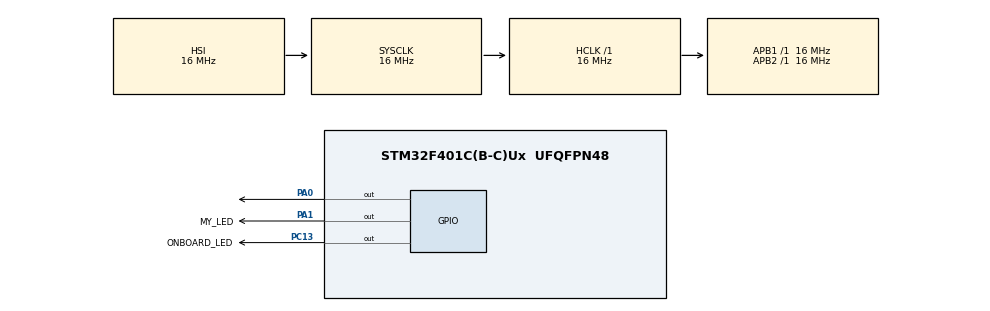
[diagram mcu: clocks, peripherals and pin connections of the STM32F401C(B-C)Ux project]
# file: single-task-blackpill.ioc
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FREERTOS.INCLUDE_vTaskDelayUntil=1
FREERTOS.Tasks01=defaultTask,0,128,StartDefaultTask,Default,NULL,Dynamic,NULL,NULL
Mcu.Family=STM32F4
Mcu.Name=STM32F401C(B-C)Ux
Mcu.Package=UFQFPN48
NVIC.PriorityGroup=NVIC_PRIORITYGROUP_4
NVIC.TIM1_UP_TIM10_IRQn=true\:15\:0\:false\:false\:true\:false\:false\:true\:true
NVIC.TimeBase=TIM1_UP_TIM10_IRQn
NVIC.TimeBaseIP=TIM1
PA0-WKUP.Signal=GPIO_Output
PA1.GPIO_Label=MY_LED
PA1.Signal=GPIO_Output
PC13-ANTI_TAMP.GPIO_Label=ONBOARD_LED
PC13-ANTI_TAMP.Signal=GPIO_Output
ProjectManager.HeapSize=0x200
ProjectManager.StackSize=0x400
ProjectManager.TargetToolchain=STM32CubeIDE
RCC.AHBFreq_Value=16000000
RCC.APB1Freq_Value=16000000
RCC.APB2Freq_Value=16000000
RCC.CortexFreq_Value=16000000
RCC.HSE_VALUE=25000000
RCC.HSI_VALUE=16000000
RCC.LSE_VALUE=32768
RCC.SYSCLKFreq_VALUE=16000000
RCC.VCOOutputFreq_Value=192000000
VP_FREERTOS_VS_CMSIS_V1.Mode=CMSIS_V1
VP_SYS_VS_tim1.Mode=TIM1
board=custom

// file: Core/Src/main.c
/* USER CODE BEGIN Header */
/**
  ******************************************************************************
  * @file           : main.c
  * @brief          : Main program body
  ******************************************************************************
  * @attention
  *
  * Copyright (c) 2025 STMicroelectronics.
  * All rights reserved.
  *
  * This software is licensed under terms that can be found in the LICENSE file
  * in the root directory of this software component.
  * If no LICENSE file comes with this software, it is provided AS-IS.
  *
  ******************************************************************************
  */
/* USER CODE END Header */
#include "main.h"
#include "cmsis_os.h"

osThreadId defaultTaskHandle;
/* USER CODE BEGIN PV */

osThreadId led_blink_primitive_handle;
osThreadId led_delay_until_handle;
osThreadId led_green_blink_handle;
osThreadId led_red_blink_handle;

/* USER CODE END PV */

void SystemClock_Config(void);
static void MX_GPIO_Init(void);
void StartDefaultTask(void const * argument);

/* USER CODE BEGIN PFP */

// declare out primitive blink task
void led_blink_primitive_task(void const * pvParameters);
void led_delay_until_task(void const* pvParameters);
void led_green_blink_task(void const* pvParameters);
void led_red_blink_task(void const* pvParameters);

/* USER CODE END PFP */

int main(void)
{

  /* MCU Configuration--------------------------------------------------------*/

  /* Reset of all peripherals, Initializes the Flash interface and the Systick. */
  HAL_Init();

  /* Configure the system clock */
  SystemClock_Config();

  /* Initialize all configured peripherals */
  MX_GPIO_Init();

  /* Create the thread(s) */
  /* definition and creation of defaultTask */
  osThreadDef(defaultTask, StartDefaultTask, osPriorityNormal, 0, 128);
  defaultTaskHandle = osThreadCreate(osThread(defaultTask), NULL);

  /* USER CODE BEGIN RTOS_THREADS */
  /* add threads, ... */

  // blink LED using RTOS primitive API -> vTask Delay
//  osThreadDef(primitive_task, led_blink_primitive_task, osPriorityNormal, 0, 128);
//  led_blink_primitive_handle = osThreadCreate(osThread(primitive_task), NULL);
//
//  osThreadDef(delay_until, led_delay_until_task, osPriorityNormal, 0, 128);
//  led_delay_until_handle = osThreadCreate(osThread(delay_until), NULL);

  // EXERCISE 3 -> blink LEDs at different frequencies
  osThreadDef(green_blink, led_green_blink_task, osPriorityNormal, 0, 128);
  led_green_blink_handle = osThreadCreate(osThread(green_blink), NULL);

  osThreadDef(red_blink, led_red_blink_task, osPriorityNormal, 0, 128);
  led_red_blink_handle = osThreadCreate(osThread(red_blink), NULL);

  /* USER CODE END RTOS_THREADS */

  /* Start scheduler */
  osKernelStart();

  /* We should never get here as control is now taken by the scheduler */
  /* Infinite loop */
  while (1)
  {

  }
}

void SystemClock_Config(void)
{
  RCC_OscInitTypeDef RCC_OscInitStruct = {0};
  RCC_ClkInitTypeDef RCC_ClkInitStruct = {0};

  /** Configure the main internal regulator output voltage
  */
  __HAL_RCC_PWR_CLK_ENABLE();
  __HAL_PWR_VOLTAGESCALING_CONFIG(PWR_REGULATOR_VOLTAGE_SCALE2);

  /** Initializes the RCC Oscillators according to the specified parameters
  * in the RCC_OscInitTypeDef structure.
  */
  RCC_OscInitStruct.OscillatorType = RCC_OSCILLATORTYPE_HSI;
  RCC_OscInitStruct.HSIState = RCC_HSI_ON;
  RCC_OscInitStruct.HSICalibrationValue = RCC_HSICALIBRATION_DEFAULT;
  RCC_OscInitStruct.PLL.PLLState = RCC_PLL_NONE;
  if (HAL_RCC_OscConfig(&RCC_OscInitStruct) != HAL_OK)
  {
    Error_Handler();
  }

  /** Initializes the CPU, AHB and APB buses clocks
  */
  RCC_ClkInitStruct.ClockType = RCC_CLOCKTYPE_HCLK|RCC_CLOCKTYPE_SYSCLK
                              |RCC_CLOCKTYPE_PCLK1|RCC_CLOCKTYPE_PCLK2;
  RCC_ClkInitStruct.SYSCLKSource = RCC_SYSCLKSOURCE_HSI;
  RCC_ClkInitStruct.AHBCLKDivider = RCC_SYSCLK_DIV1;
  RCC_ClkInitStruct.APB1CLKDivider = RCC_HCLK_DIV1;
  RCC_ClkInitStruct.APB2CLKDivider = RCC_HCLK_DIV1;

  if (HAL_RCC_ClockConfig(&RCC_ClkInitStruct, FLASH_LATENCY_0) != HAL_OK)
  {
    Error_Handler();
  }
}

static void MX_GPIO_Init(void)
{
  GPIO_InitTypeDef GPIO_InitStruct = {0};

  /* GPIO Ports Clock Enable */
  __HAL_RCC_GPIOC_CLK_ENABLE();
  __HAL_RCC_GPIOA_CLK_ENABLE();

  /*Configure GPIO pin Output Level */
  HAL_GPIO_WritePin(ONBOARD_LED_GPIO_Port, ONBOARD_LED_Pin, GPIO_PIN_RESET);

  /*Configure GPIO pin Output Level */
  HAL_GPIO_WritePin(GPIOA, GPIO_PIN_0|MY_LED_Pin, GPIO_PIN_RESET);

  /*Configure GPIO pin : ONBOARD_LED_Pin */
  GPIO_InitStruct.Pin = ONBOARD_LED_Pin;
  GPIO_InitStruct.Mode = GPIO_MODE_OUTPUT_PP;
  GPIO_InitStruct.Pull = GPIO_NOPULL;
  GPIO_InitStruct.Speed = GPIO_SPEED_FREQ_LOW;
  HAL_GPIO_Init(ONBOARD_LED_GPIO_Port, &GPIO_InitStruct);

  /*Configure GPIO pins : PA0 MY_LED_Pin */
  GPIO_InitStruct.Pin = GPIO_PIN_0|MY_LED_Pin;
  GPIO_InitStruct.Mode = GPIO_MODE_OUTPUT_PP;
  GPIO_InitStruct.Pull = GPIO_NOPULL;
  GPIO_InitStruct.Speed = GPIO_SPEED_FREQ_LOW;
  HAL_GPIO_Init(GPIOA, &GPIO_InitStruct);

}

/* USER CODE BEGIN 4 */
void led_blink_primitive_task(void const* pvParameters) {
	while(1) {
		HAL_GPIO_WritePin(MY_LED_GPIO_Port, MY_LED_Pin, GPIO_PIN_SET);
		vTaskDelay(500);
		HAL_GPIO_WritePin(MY_LED_GPIO_Port, MY_LED_Pin, GPIO_PIN_RESET);
		vTaskDelay(500);
	}
}

void led_delay_until_task(void const* pvParameters) {
	TickType_t timestamp;
	TickType_t delay_ms = 2000;

	while(1) {
		HAL_GPIO_WritePin(MY_LED_GPIO_Port, MY_LED_Pin, GPIO_PIN_SET);
		osDelayUntil(&timestamp, delay_ms);
		HAL_GPIO_WritePin(MY_LED_GPIO_Port, MY_LED_Pin, GPIO_PIN_RESET);
		osDelayUntil(&timestamp, delay_ms);
	}
}

void led_green_blink_task(void const* pvParameters) {
	while(1) {
		HAL_GPIO_TogglePin(MY_LED_GPIO_Port, MY_LED_Pin);
		vTaskDelay(2000);
	}
}

void led_red_blink_task(void const* pvParameters) {
	while(1) {
		HAL_GPIO_TogglePin(ONBOARD_LED_GPIO_Port, ONBOARD_LED_Pin);
		vTaskDelay(500);
	}
}

/* USER CODE END 4 */

void StartDefaultTask(void const * argument)
{
  for(;;)
  {
    osDelay(1);
  }
}

void HAL_TIM_PeriodElapsedCallback(TIM_HandleTypeDef *htim)
{
  if (htim->Instance == TIM1) {
    HAL_IncTick();
  }
}

void Error_Handler(void)
{
  __disable_irq();
  while (1)
  {
  }
}
